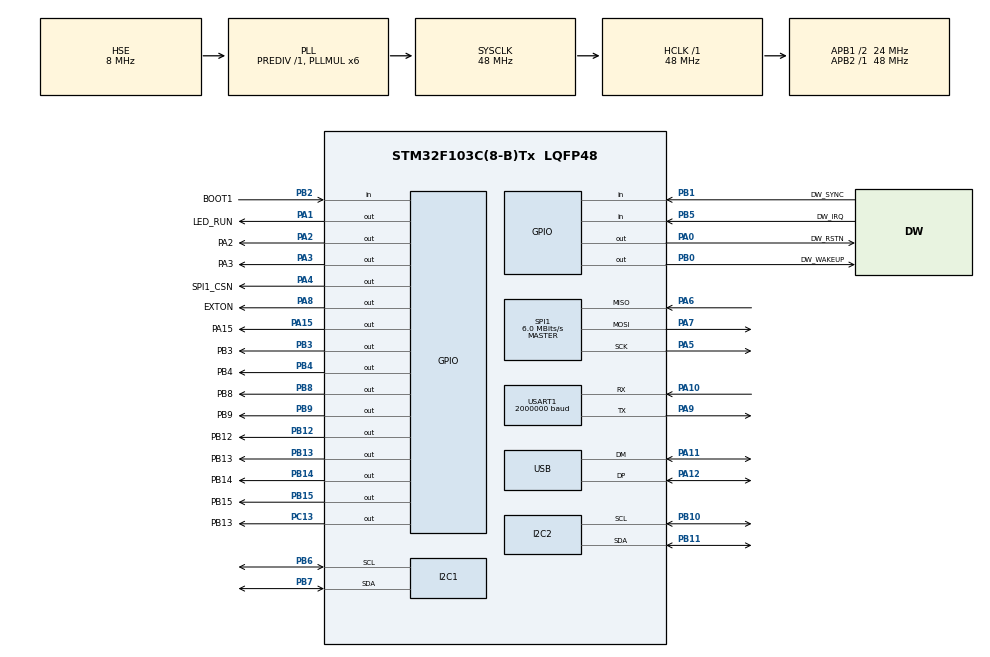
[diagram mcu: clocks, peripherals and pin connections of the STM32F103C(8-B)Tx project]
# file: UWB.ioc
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Dma.Request0=USART1_RX
Dma.Request1=USART1_TX
Dma.USART1_RX.0.Direction=DMA_PERIPH_TO_MEMORY
Dma.USART1_RX.0.Instance=DMA1_Channel5
Dma.USART1_RX.0.MemDataAlignment=DMA_MDATAALIGN_BYTE
Dma.USART1_RX.0.MemInc=DMA_MINC_ENABLE
Dma.USART1_RX.0.Mode=DMA_CIRCULAR
Dma.USART1_RX.0.PeriphDataAlignment=DMA_PDATAALIGN_BYTE
Dma.USART1_RX.0.PeriphInc=DMA_PINC_DISABLE
Dma.USART1_RX.0.Priority=DMA_PRIORITY_LOW
Dma.USART1_TX.1.Direction=DMA_MEMORY_TO_PERIPH
Dma.USART1_TX.1.Instance=DMA1_Channel4
Dma.USART1_TX.1.MemDataAlignment=DMA_MDATAALIGN_BYTE
Dma.USART1_TX.1.MemInc=DMA_MINC_ENABLE
Dma.USART1_TX.1.Mode=DMA_NORMAL
Dma.USART1_TX.1.PeriphDataAlignment=DMA_PDATAALIGN_BYTE
Dma.USART1_TX.1.PeriphInc=DMA_PINC_DISABLE
Dma.USART1_TX.1.Priority=DMA_PRIORITY_LOW
Mcu.Family=STM32F1
Mcu.Name=STM32F103C(8-B)Tx
Mcu.Package=LQFP48
NVIC.DMA1_Channel4_IRQn=true\:0\:0\:false\:false\:true\:false\:true\:true
NVIC.DMA1_Channel5_IRQn=true\:0\:0\:false\:false\:true\:false\:true\:true
NVIC.PriorityGroup=NVIC_PRIORITYGROUP_4
NVIC.USART1_IRQn=true\:0\:0\:false\:false\:true\:true\:true\:true
PA0-WKUP.GPIO_Label=DW_RSTN
PA0-WKUP.Signal=GPIO_Output
PA1.GPIO_Label=LED_RUN
PA1.Signal=GPIO_Output
PA10.Mode=Asynchronous
PA10.Signal=USART1_RX
PA11.Mode=Device
PA11.Signal=USB_DM
PA12.Mode=Device
PA12.Signal=USB_DP
PA13.GPIO_Label=SWDIO
PA13.Mode=Serial_Wire
PA13.Signal=SYS_JTMS-SWDIO
PA14.GPIO_Label=SWCLK
PA14.Mode=Serial_Wire
PA14.Signal=SYS_JTCK-SWCLK
PA15.GPIO_Label=PA15
PA15.Signal=GPIO_Output
PA2.GPIO_Label=PA2
PA2.Signal=GPIO_Output
PA3.GPIO_Label=PA3
PA3.Signal=GPIO_Output
PA4.GPIO_Label=SPI1_CSN
PA4.Signal=GPIO_Output
PA5.Mode=Full_Duplex_Master
PA5.Signal=SPI1_SCK
PA6.Mode=Full_Duplex_Master
PA6.Signal=SPI1_MISO
PA7.Mode=Full_Duplex_Master
PA7.Signal=SPI1_MOSI
PA8.GPIO_Label=EXTON
PA8.Signal=GPIO_Output
PA9.Mode=Asynchronous
PA9.Signal=USART1_TX
PB0.GPIO_Label=DW_WAKEUP
PB0.Signal=GPIO_Output
PB1.GPIO_Label=DW_SYNC
PB1.Signal=GPIO_Input
PB10.Mode=I2C
PB10.Signal=I2C2_SCL
PB11.Mode=I2C
PB11.Signal=I2C2_SDA
PB12.GPIO_Label=PB12
PB12.Signal=GPIO_Output
PB13.GPIO_Label=PB13
PB13.Signal=GPIO_Output
PB14.GPIO_Label=PB14
PB14.Signal=GPIO_Output
PB15.GPIO_Label=PB15
PB15.Signal=GPIO_Output
PB2.GPIO_Label=BOOT1
PB2.Signal=GPIO_Input
PB3.GPIO_Label=PB3
PB3.Signal=GPIO_Output
PB4.GPIO_Label=PB4
PB4.Signal=GPIO_Output
PB5.GPIO_Label=DW_IRQ
PB5.Signal=GPIO_Input
PB6.Mode=I2C
PB6.Signal=I2C1_SCL
PB7.Mode=I2C
PB7.Signal=I2C1_SDA
PB8.GPIO_Label=PB8
PB8.Signal=GPIO_Output
PB9.GPIO_Label=PB9
PB9.Signal=GPIO_Output
PC13-TAMPER-RTC.GPIO_Label=PB13
PC13-TAMPER-RTC.Signal=GPIO_Output
PC14-OSC32_IN.Mode=LSE-External-Oscillator
PC14-OSC32_IN.Signal=RCC_OSC32_IN
PC15-OSC32_OUT.Mode=LSE-External-Oscillator
PC15-OSC32_OUT.Signal=RCC_OSC32_OUT
PD0-OSC_IN.Mode=HSE-External-Oscillator
PD0-OSC_IN.Signal=RCC_OSC_IN
PD1-OSC_OUT.Mode=HSE-External-Oscillator
PD1-OSC_OUT.Signal=RCC_OSC_OUT
ProjectManager.HeapSize=0x200
ProjectManager.StackSize=0x400
ProjectManager.TargetToolchain=CMake
RCC.AHBFreq_Value=48000000
RCC.APB1CLKDivider=RCC_HCLK_DIV2
RCC.APB1Freq_Value=24000000
RCC.APB1TimFreq_Value=48000000
RCC.APB2Freq_Value=48000000
RCC.APB2TimFreq_Value=48000000
RCC.HCLKFreq_Value=48000000
RCC.PLLMUL=RCC_PLL_MUL6
RCC.SYSCLKFreq_VALUE=48000000
RCC.SYSCLKSource=RCC_SYSCLKSOURCE_PLLCLK
RCC.USBFreq_Value=48000000
SPI1.BaudRatePrescaler=SPI_BAUDRATEPRESCALER_8
SPI1.CalculateBaudRate=6.0 MBits/s
SPI1.Direction=SPI_DIRECTION_2LINES
SPI1.Mode=SPI_MODE_MASTER
SPI1.VirtualType=VM_MASTER
USART1.BaudRate=2000000
USART1.VirtualMode=VM_ASYNC
board=custom

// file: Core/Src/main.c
#include "main.h"

#include <stdbool.h>

#include "app.h"
#include "OLED/oled.h"
#include "UWB/uwb.h"

I2C_HandleTypeDef hi2c1;
I2C_HandleTypeDef hi2c2;

SPI_HandleTypeDef hspi1;

UART_HandleTypeDef huart1;
DMA_HandleTypeDef hdma_usart1_rx;
DMA_HandleTypeDef hdma_usart1_tx;

PCD_HandleTypeDef hpcd_USB_FS;

void SystemClock_Config(void);

static void MX_GPIO_Init(void);

static void MX_DMA_Init(void);

static void MX_I2C1_Init(void);

static void MX_I2C2_Init(void);

static void MX_SPI1_Init(void);

static void MX_USART1_UART_Init(void);

static void MX_USB_PCD_Init(void);

int main(void) {

    /* MCU Configuration--------------------------------------------------------*/

    /* Reset of all peripherals, Initializes the Flash interface and the Systick. */
    HAL_Init();

    /* Configure the system clock */
    SystemClock_Config();

    /* Initialize all configured peripherals */
    MX_GPIO_Init();
    MX_DMA_Init();
    MX_I2C1_Init();
    MX_I2C2_Init();
    MX_SPI1_Init();
    MX_USART1_UART_Init();
    MX_USB_PCD_Init();

    OLED_Init(&hi2c1);

    /* 应用初始化（OLED/UWB/发现/校准封装至 app） */
    app_init(&hi2c1);

    while (1) {
        app_process();
    }
}

void SystemClock_Config(void) {
    RCC_OscInitTypeDef RCC_OscInitStruct = {0};
    RCC_ClkInitTypeDef RCC_ClkInitStruct = {0};
    RCC_PeriphCLKInitTypeDef PeriphClkInit = {0};

    /** Initializes the RCC Oscillators according to the specified parameters
    * in the RCC_OscInitTypeDef structure.
    */
    RCC_OscInitStruct.OscillatorType = RCC_OSCILLATORTYPE_HSE;
    RCC_OscInitStruct.HSEState = RCC_HSE_ON;
    RCC_OscInitStruct.HSEPredivValue = RCC_HSE_PREDIV_DIV1;
    RCC_OscInitStruct.HSIState = RCC_HSI_ON;
    RCC_OscInitStruct.PLL.PLLState = RCC_PLL_ON;
    RCC_OscInitStruct.PLL.PLLSource = RCC_PLLSOURCE_HSE;
    RCC_OscInitStruct.PLL.PLLMUL = RCC_PLL_MUL6;
    if (HAL_RCC_OscConfig(&RCC_OscInitStruct) != HAL_OK) {
        Error_Handler();
    }

    /** Initializes the CPU, AHB and APB buses clocks
    */
    RCC_ClkInitStruct.ClockType = RCC_CLOCKTYPE_HCLK | RCC_CLOCKTYPE_SYSCLK
                                  | RCC_CLOCKTYPE_PCLK1 | RCC_CLOCKTYPE_PCLK2;
    RCC_ClkInitStruct.SYSCLKSource = RCC_SYSCLKSOURCE_PLLCLK;
    RCC_ClkInitStruct.AHBCLKDivider = RCC_SYSCLK_DIV1;
    RCC_ClkInitStruct.APB1CLKDivider = RCC_HCLK_DIV2;
    RCC_ClkInitStruct.APB2CLKDivider = RCC_HCLK_DIV1;

    if (HAL_RCC_ClockConfig(&RCC_ClkInitStruct, FLASH_LATENCY_1) != HAL_OK) {
        Error_Handler();
    }
    PeriphClkInit.PeriphClockSelection = RCC_PERIPHCLK_USB;
    PeriphClkInit.UsbClockSelection = RCC_USBCLKSOURCE_PLL;
    if (HAL_RCCEx_PeriphCLKConfig(&PeriphClkInit) != HAL_OK) {
        Error_Handler();
    }
}

static void MX_I2C1_Init(void) {

    hi2c1.Instance = I2C1;
    hi2c1.Init.ClockSpeed = 100000;
    hi2c1.Init.DutyCycle = I2C_DUTYCYCLE_2;
    hi2c1.Init.OwnAddress1 = 0;
    hi2c1.Init.AddressingMode = I2C_ADDRESSINGMODE_7BIT;
    hi2c1.Init.DualAddressMode = I2C_DUALADDRESS_DISABLE;
    hi2c1.Init.OwnAddress2 = 0;
    hi2c1.Init.GeneralCallMode = I2C_GENERALCALL_DISABLE;
    hi2c1.Init.NoStretchMode = I2C_NOSTRETCH_DISABLE;
    if (HAL_I2C_Init(&hi2c1) != HAL_OK) {
        Error_Handler();
    }
}

static void MX_I2C2_Init(void) {

    hi2c2.Instance = I2C2;
    hi2c2.Init.ClockSpeed = 100000;
    hi2c2.Init.DutyCycle = I2C_DUTYCYCLE_2;
    hi2c2.Init.OwnAddress1 = 0;
    hi2c2.Init.AddressingMode = I2C_ADDRESSINGMODE_7BIT;
    hi2c2.Init.DualAddressMode = I2C_DUALADDRESS_DISABLE;
    hi2c2.Init.OwnAddress2 = 0;
    hi2c2.Init.GeneralCallMode = I2C_GENERALCALL_DISABLE;
    hi2c2.Init.NoStretchMode = I2C_NOSTRETCH_DISABLE;
    if (HAL_I2C_Init(&hi2c2) != HAL_OK) {
        Error_Handler();
    }
}

static void MX_SPI1_Init(void) {

    /* SPI1 parameter configuration*/
    hspi1.Instance = SPI1;
    hspi1.Init.Mode = SPI_MODE_MASTER;
    hspi1.Init.Direction = SPI_DIRECTION_2LINES;
    hspi1.Init.DataSize = SPI_DATASIZE_8BIT;
    hspi1.Init.CLKPolarity = SPI_POLARITY_LOW;
    hspi1.Init.CLKPhase = SPI_PHASE_1EDGE;
    hspi1.Init.NSS = SPI_NSS_SOFT;
    hspi1.Init.BaudRatePrescaler = SPI_BAUDRATEPRESCALER_8;
    hspi1.Init.FirstBit = SPI_FIRSTBIT_MSB;
    hspi1.Init.TIMode = SPI_TIMODE_DISABLE;
    hspi1.Init.CRCCalculation = SPI_CRCCALCULATION_DISABLE;
    hspi1.Init.CRCPolynomial = 10;
    if (HAL_SPI_Init(&hspi1) != HAL_OK) {
        Error_Handler();
    }
}

static void MX_USART1_UART_Init(void) {

    huart1.Instance = USART1;
    huart1.Init.BaudRate = 2000000;
    huart1.Init.WordLength = UART_WORDLENGTH_8B;
    huart1.Init.StopBits = UART_STOPBITS_1;
    huart1.Init.Parity = UART_PARITY_NONE;
    huart1.Init.Mode = UART_MODE_TX_RX;
    huart1.Init.HwFlowCtl = UART_HWCONTROL_NONE;
    huart1.Init.OverSampling = UART_OVERSAMPLING_16;
    if (HAL_UART_Init(&huart1) != HAL_OK) {
        Error_Handler();
    }
}

static void MX_USB_PCD_Init(void) {

    hpcd_USB_FS.Instance = USB;
    hpcd_USB_FS.Init.dev_endpoints = 8;
    hpcd_USB_FS.Init.speed = PCD_SPEED_FULL;
    hpcd_USB_FS.Init.low_power_enable = DISABLE;
    hpcd_USB_FS.Init.lpm_enable = DISABLE;
    hpcd_USB_FS.Init.battery_charging_enable = DISABLE;
    if (HAL_PCD_Init(&hpcd_USB_FS) != HAL_OK) {
        Error_Handler();
    }
}

static void MX_DMA_Init(void) {
    /* DMA controller clock enable */
    __HAL_RCC_DMA1_CLK_ENABLE();

    /* DMA interrupt init */
    /* DMA1_Channel4_IRQn interrupt configuration */
    HAL_NVIC_SetPriority(DMA1_Channel4_IRQn, 0, 0);
    HAL_NVIC_EnableIRQ(DMA1_Channel4_IRQn);
    /* DMA1_Channel5_IRQn interrupt configuration */
    HAL_NVIC_SetPriority(DMA1_Channel5_IRQn, 0, 0);
    HAL_NVIC_EnableIRQ(DMA1_Channel5_IRQn);
}

static void MX_GPIO_Init(void) {
    GPIO_InitTypeDef GPIO_InitStruct = {0};

    /* GPIO Ports Clock Enable */
    __HAL_RCC_GPIOC_CLK_ENABLE();
    __HAL_RCC_GPIOD_CLK_ENABLE();
    __HAL_RCC_GPIOA_CLK_ENABLE();
    __HAL_RCC_GPIOB_CLK_ENABLE();

    /*Configure GPIO pin Output Level */
    HAL_GPIO_WritePin(PB13_GPIO_Port, PB13_Pin, GPIO_PIN_RESET);

    /*Configure GPIO pin Output Level */
    HAL_GPIO_WritePin(GPIOA, DW_RSTN_Pin | LED_RUN_Pin | PA2_Pin | PA3_Pin
                             | SPI1_CSN_Pin | EXTON_Pin | PA15_Pin, GPIO_PIN_RESET);

    /*Configure GPIO pin Output Level */
    HAL_GPIO_WritePin(GPIOB, DW_WAKEUP_Pin | PB12_Pin | PB13B13_Pin | PB14_Pin
                             | PB15_Pin | PB3_Pin | PB4_Pin | PB8_Pin
                             | PB9_Pin, GPIO_PIN_RESET);

    /*Configure GPIO pin : PB13_Pin */
    GPIO_InitStruct.Pin = PB13_Pin;
    GPIO_InitStruct.Mode = GPIO_MODE_OUTPUT_PP;
    GPIO_InitStruct.Pull = GPIO_NOPULL;
    GPIO_InitStruct.Speed = GPIO_SPEED_FREQ_LOW;
    HAL_GPIO_Init(PB13_GPIO_Port, &GPIO_InitStruct);

    /*Configure GPIO pins : DW_RSTN_Pin LED_RUN_Pin PA2_Pin PA3_Pin
                             SPI1_CSN_Pin EXTON_Pin PA15_Pin */
    GPIO_InitStruct.Pin = DW_RSTN_Pin | LED_RUN_Pin | PA2_Pin | PA3_Pin
                          | SPI1_CSN_Pin | EXTON_Pin | PA15_Pin;
    GPIO_InitStruct.Mode = GPIO_MODE_OUTPUT_PP;
    GPIO_InitStruct.Pull = GPIO_NOPULL;
    GPIO_InitStruct.Speed = GPIO_SPEED_FREQ_LOW;
    HAL_GPIO_Init(GPIOA, &GPIO_InitStruct);

    ///////////////////////////////
    /*Configure GPIO pins : DW_WAKEUP_Pin DW_SYNC_Pin PB12_Pin PB13_Pin
                             PB14_Pin PB15_Pin PB3_Pin PB4_Pin
                             PB8_Pin PB9_Pin */
    GPIO_InitStruct.Pin = DW_WAKEUP_Pin | DW_SYNC_Pin | PB12_Pin | PB13_Pin
                          | PB14_Pin | PB15_Pin | PB3_Pin | PB4_Pin
                          | PB8_Pin | PB9_Pin;
    GPIO_InitStruct.Mode = GPIO_MODE_OUTPUT_PP;
    GPIO_InitStruct.Pull = GPIO_NOPULL;
    GPIO_InitStruct.Speed = GPIO_SPEED_FREQ_LOW;
    HAL_GPIO_Init(GPIOB, &GPIO_InitStruct);

    /*Configure GPIO pin : BOOT1_Pin */
    GPIO_InitStruct.Pin = BOOT1_Pin;
    GPIO_InitStruct.Mode = GPIO_MODE_INPUT;
    GPIO_InitStruct.Pull = GPIO_NOPULL;
    HAL_GPIO_Init(BOOT1_GPIO_Port, &GPIO_InitStruct);

    /*Configure GPIO pin : DW_SYNC_Pin */
    GPIO_InitStruct.Pin = DW_SYNC_Pin;
    GPIO_InitStruct.Mode = GPIO_MODE_INPUT;
    GPIO_InitStruct.Pull = GPIO_NOPULL;
    HAL_GPIO_Init(DW_SYNC_GPIO_Port, &GPIO_InitStruct);

    // ... existing code ...
    /* 正确配置 DW_IRQ_Pin 为外部中断输入（主动高，上升沿触发） */
    GPIO_InitStruct.Pin = DW_IRQ_Pin;
    GPIO_InitStruct.Mode = GPIO_MODE_IT_RISING;
    GPIO_InitStruct.Pull = GPIO_PULLDOWN; /* 硬件若已下拉可改为 GPIO_NOPULL */
    HAL_GPIO_Init(DW_IRQ_GPIO_Port, &GPIO_InitStruct);

    /* 使能 EXTI9_5 中断 */
    HAL_NVIC_SetPriority(EXTI9_5_IRQn, 5, 0);
    HAL_NVIC_EnableIRQ(EXTI9_5_IRQn);
}

/* USER CODE BEGIN 4 */
/* 应用回调与显示逻辑已迁移至 app.c */
/* USER CODE END 4 */

void Error_Handler(void) {
    __disable_irq();
    while (1) {
    }
}
